# CY8C4248BZI_L489 register map
File version: 0.1
PSoC 4200L
Registers are 32-bit, read-write, no defined reset value unless marked. A register's access mark holds for its fields unless they carry their own. Offsets are from the block's base; lines under a group give offsets from that group; [hi:lo] are bit positions; {n}, {i} and the like mark numbered series; 'fields as' and 'values as' point back to an identical list; <NAME> marks a mode.

## Memory map
0x00000000 LED_RED_PWM
0x00000000 USBUART — USBFS
0x00000000 SPI — Serial Communication Block
0x00000000 DMAC — DMAC Registers
0x00000000 LED_BLUE_PWM
0x00000000 LED_GREEN_PWM
0x00000000 ByteCounter_Tx
0x00000000 ByteCounter_Rx
0x00000000 I2S
0x00000000 Async_Feedback_Counter
0x00000000 ADC — Sequencing SAR ADC
0x00000000 AudioClkSel
0x00000000 CodecI2CM — Serial Communication Block
0x00000000 UART — Serial Communication Block

## LED_RED_PWM
Base 0x00000000
0x402002C8 COUNTER — Current counter value
0x402002CC CC — Compare / capture value
0x402002D0 CC_BUF — Compare / capture buffer value
0x402002D4 PERIOD — Period value
0x402002D8 PERIOD_BUF — Period buffer value

## LED_BLUE_PWM
Base 0x00000000
0x40200288 COUNTER — Current counter value
0x4020028C CC — Compare / capture value
0x40200290 CC_BUF — Compare / capture buffer value
0x40200294 PERIOD — Period value
0x40200298 PERIOD_BUF — Period buffer value

## LED_GREEN_PWM
Base 0x00000000
0x40200248 COUNTER — Current counter value
0x4020024C CC — Compare / capture value
0x40200250 CC_BUF — Compare / capture buffer value
0x40200254 PERIOD — Period value
0x40200258 PERIOD_BUF — Period buffer value

## ByteCounter_Tx
Base 0x00000000
0x40200108 COUNTER — Current counter value
0x4020010C CC — Compare / capture value
0x40200110 CC_BUF — Compare / capture buffer value
0x40200114 PERIOD — Period value
0x40200118 PERIOD_BUF — Period buffer value

## ByteCounter_Rx
Base 0x00000000
0x40200148 COUNTER — Current counter value
0x4020014C CC — Compare / capture value
0x40200150 CC_BUF — Compare / capture buffer value
0x40200154 PERIOD — Period value
0x40200158 PERIOD_BUF — Period buffer value

## I2S
Base 0x00000000
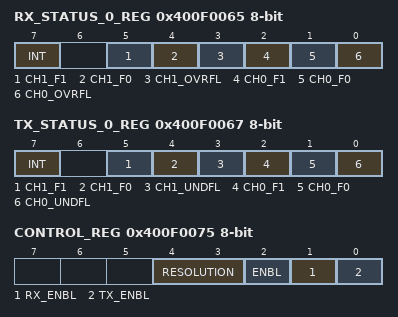
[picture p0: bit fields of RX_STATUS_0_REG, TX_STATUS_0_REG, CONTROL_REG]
0x400F0065 RX_STATUS_0_REG 8-bit
  [7] INT ro — Interrupt bit
  [5] CH1_F1 ro — Stereo channel 1 FIFO 1 state
    0=EMPTY; 1=NOT_EMPTY
  [4] CH1_F0 ro — Stereo channel 1 FIFO 0 state
    0=EMPTY; 1=NOT_EMPTY
  [3] CH1_OVRFL ro — Stereo channel 1 FIFO overflow
    0=NO_OVERFLOW; 1=OVERFLOW
  [2] CH0_F1 ro — Stereo channel 0 FIFO 1 state
    0=EMPTY; 1=NOT_EMPTY
  [1] CH0_F0 ro — Stereo channel 0 FIFO 0 state
    0=EMPTY; 1=NOT_EMPTY
  [0] CH0_OVRFL ro — Stereo channel 0 FIFO overflow
    0=NO_OVERFLOW; 1=OVERFLOW
0x400F0067 TX_STATUS_0_REG 8-bit
  [7] INT ro — Interrupt bit
  [5] CH1_F1 ro — Stereo channel 1 FIFO 1 state
    0=FULL; 1=NOT_FULL
  [4] CH1_F0 ro — Stereo channel 1 FIFO 0 state
    0=FULL; 1=NOT_FULL
  [3] CH1_UNDFL ro — Stereo channel 1 FIFO underflow
    0=NO_UNDERFLOW; 1=UNDERFLOW
  [2] CH0_F1 ro — Stereo channel 0 FIFO 1 state
    0=FULL; 1=NOT_FULL
  [1] CH0_F0 ro — Stereo channel 0 FIFO 0 state
    0=FULL; 1=NOT_FULL
  [0] CH0_UNDFL ro — Stereo channel 0 FIFO underflow
    0=NO_UNDERFLOW; 1=UNDERFLOW
0x400F0075 CONTROL_REG 8-bit
  [4:3] RESOLUTION — Specifies data bits value. Applicable only if dynamic bit resolution is selected.
    0=Cy8_BIT; 1=Cy16_BIT; 2=Cy24_BIT; 3=Cy32_BIT
  [2] ENBL — Starts the generation of the WS and SCK outputs.
    1=ENABLED; 0=DISABLED
  [1] RX_ENBL — Enables Rx direction. Applicable only if Rx direction presents for the component.
    1=ENABLED; 0=DISABLED
  [0] TX_ENBL — Enables Tx direction. Applicable only if Tx direction presents for the component.
    1=ENABLED; 0=DISABLED

## Async_Feedback_Counter
Base 0x00000000
0x400F0001 Async_Feedback_Counter_COUNTER 8-bit — UDB.A0 - Current Down Counter Value
0x400F0021 Async_Feedback_Counter_PERIOD 8-bit — UDB.D0 - Assigned Period
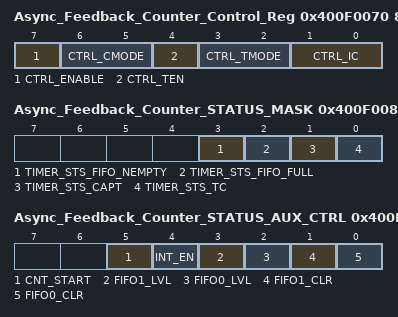
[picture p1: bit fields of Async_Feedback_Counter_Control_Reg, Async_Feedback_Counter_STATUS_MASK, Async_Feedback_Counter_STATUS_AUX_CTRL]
0x400F0070 Async_Feedback_Counter_Control_Reg 8-bit — UDB Control Register - Assigned Control Register Value
  [7] CTRL_ENABLE — Enable the Timer
  [6:5] CTRL_CMODE — Capture Mode
  [4] CTRL_TEN — Trigger Enable Bit
  [3:2] CTRL_TMODE — Trigger Mode
  [1:0] CTRL_IC — Interrupt Count
0x400F0081 Async_Feedback_Counter_STATUS_MASK 8-bit — UDB Status bits Interrupt Mask Enable Register
  [3] TIMER_STS_FIFO_NEMPTY ro — FIFO Empty status
  [2] TIMER_STS_FIFO_FULL ro — FIFO Full Status
  [1] TIMER_STS_CAPT ro — Enables the Interrupt on Capture
  [0] TIMER_STS_TC ro — Enables the Interrupt on TC
0x400F0091 Async_Feedback_Counter_STATUS_AUX_CTRL 8-bit — UDB Auxilliary Control Register
  [5] CNT_START — FIFO0 clear
    0=E_CNT_START0 (Disable counter); 1=E_CNT_START1 (Enable counter)
  [4] INT_EN
    0=E_INT_EN0 (Interrupt disabled); 1=E_INT_EN1 (Interrupt enabled)
  [3] FIFO1_LVL — FIFO level
    0=E_FIFO_LVL_0 (FIFO LVL: input mode: FIFO not full; output mode: FIFO not empty); 1=E_FIFO_LVL_1 (FIFO LVL: input mode: FIFO at least 1/2 empty; output mode: FIFO at least 1/2 full)
  [2] FIFO0_LVL — FIFO level
    values as FIFO1_LVL
  [1] FIFO1_CLR — FIFO1 clear
    0=E_FIFO_CLR_0 (Normal FIFO operation); 1=E_FIFO_CLR_1 (Clear FIFO state)
  [0] FIFO0_CLR — FIFO0 clear
    values as FIFO1_CLR
